# STM32L4x2 register map
File version: 2.3
CPU: CM4 r0p1, little endian, MPU, FPU, 4 interrupt priority bits
Registers are 32-bit, read-write, reset 0x0 unless marked. A register's access mark holds for its fields unless they carry their own. Offsets are from the block's base; [hi:lo] are bit positions; 'fields as' and 'values as' point back to an identical list.

## CRS — Clock recovery system
Base 0x40006000
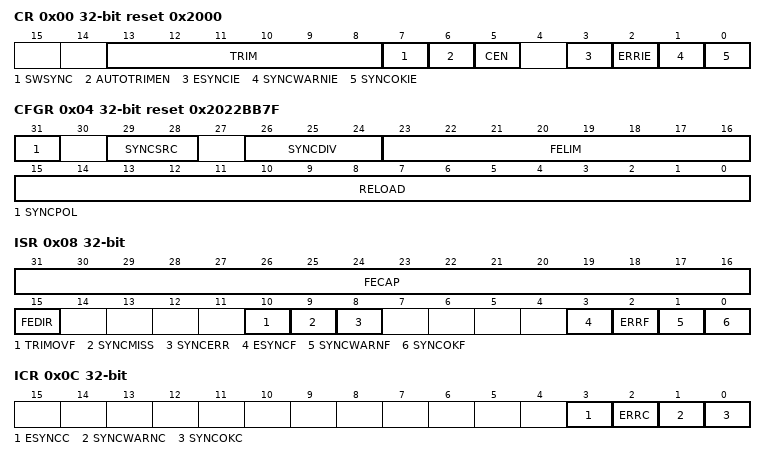
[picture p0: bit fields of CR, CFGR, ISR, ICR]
0x00 CR reset 0x2000 — control register
  [13:8] TRIM — HSI48 oscillator smooth trimming
  [7] SWSYNC — Generate software SYNC event
    1=Sync (A software sync is generated)
  [6] AUTOTRIMEN — Automatic trimming enable
    0=Disabled (Automatic trimming disabled); 1=Enabled (Automatic trimming enabled)
  [5] CEN — Frequency error counter enable
    0=Disabled (Frequency error counter disabled); 1=Enabled (Frequency error counter enabled)
  [3] ESYNCIE — Expected SYNC interrupt enable
    0=Disabled (Interrupt disabled); 1=Enabled (Interrupt enabled)
  [2] ERRIE — Synchronization or trimming error interrupt enable
    values as ESYNCIE
  [1] SYNCWARNIE — SYNC warning interrupt enable
    values as ESYNCIE
  [0] SYNCOKIE — SYNC event OK interrupt enable
    values as ESYNCIE
0x04 CFGR reset 0x2022BB7F — configuration register
  [31] SYNCPOL — SYNC polarity selection
    0=RisingEdge (SYNC active on rising edge); 1=FallingEdge (SYNC active on falling edge)
  [29:28] SYNCSRC — SYNC signal source selection
    0=GPIO_AF (GPIO AF (crs_sync_in_1) selected as SYNC signal source); 1=LSE (LSE (crs_sync_in_2) selected as SYNC signal source); 2=USB_SOF (USB SOF (crs_sync_in_3) selected as SYNC signal source)
  [26:24] SYNCDIV — SYNC divider
    0=Div1 (SYNC not divided); 1=Div2 (SYNC divided by 2); 2=Div4 (SYNC divided by 4); 3=Div8 (SYNC divided by 8); 4=Div16 (SYNC divided by 16); 5=Div32 (SYNC divided by 32); 6=Div64 (SYNC divided by 64); 7=Div128 (SYNC divided by 128)
  [23:16] FELIM — Frequency error limit
  [15:0] RELOAD — Counter reload value
0x08 ISR ro — interrupt and status register
  [31:16] FECAP — Frequency error capture
  [15] FEDIR — Frequency error direction
    0=UpCounting (Error in up-counting direction); 1=DownCounting (Error in down-counting direction)
  [10] TRIMOVF — Trimming overflow or underflow
    0=NotSignaled (Signal not set); 1=Signaled (Signal set)
  [9] SYNCMISS — SYNC missed
    0=NotSignaled (Signal not set); 1=Signaled (Signal set)
  [8] SYNCERR — SYNC error
    0=NotSignaled (Signal not set); 1=Signaled (Signal set)
  [3] ESYNCF — Expected SYNC flag
    0=NotSignaled (Signal not set); 1=Signaled (Signal set)
  [2] ERRF — Error flag
    0=NotSignaled (Signal not set); 1=Signaled (Signal set)
  [1] SYNCWARNF — SYNC warning flag
    0=NotSignaled (Signal not set); 1=Signaled (Signal set)
  [0] SYNCOKF — SYNC event OK flag
    0=NotSignaled (Signal not set); 1=Signaled (Signal set)
0x0C ICR — interrupt flag clear register
  [all] fields
    1=Clear flag
  [3] ESYNCC — Expected SYNC clear flag
  [2] ERRC — Error clear flag
  [1] SYNCWARNC — SYNC warning clear flag
  [0] SYNCOKC — SYNC event OK clear flag

## DBGMCU — MCU debug component
Base 0xE0042000
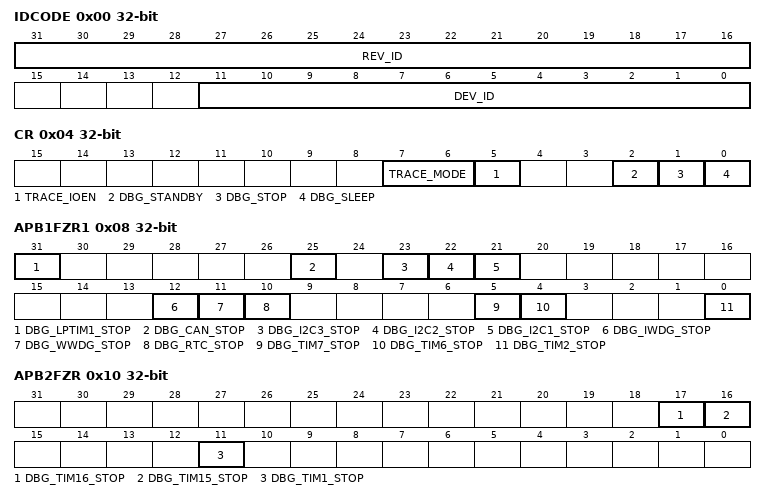
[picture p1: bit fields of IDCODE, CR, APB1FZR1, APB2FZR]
0x00 IDCODE ro — DBGMCU_IDCODE
  [31:16] REV_ID — Revision identifie
  [11:0] DEV_ID — Device identifier
0x04 CR — Debug MCU configuration register
  [7:6] TRACE_MODE — Trace pin assignment control
  [5] TRACE_IOEN — Trace pin assignment control
  [2] DBG_STANDBY — Debug Standby mode
  [1] DBG_STOP — Debug Stop mode
  [0] DBG_SLEEP — Debug Sleep mode
0x08 APB1FZR1 — Debug MCU APB1 freeze register1
  [31] DBG_LPTIM1_STOP — LPTIM1 counter stopped when core is halted
  [25] DBG_CAN_STOP — bxCAN stopped when core is halted
  [23] DBG_I2C3_STOP — I2C3 SMBUS timeout counter stopped when core is halted
  [22] DBG_I2C2_STOP — I2C2 SMBUS timeout counter stopped when core is halted
  [21] DBG_I2C1_STOP — I2C1 SMBUS timeout counter stopped when core is halted
  [12] DBG_IWDG_STOP — Independent watchdog counter stopped when core is halted
  [11] DBG_WWDG_STOP — Window watchdog counter stopped when core is halted
  [10] DBG_RTC_STOP — RTC counter stopped when core is halted
  [5] DBG_TIM7_STOP — TIM7 counter stopped when core is halted
  [4] DBG_TIM6_STOP — TIM6 counter stopped when core is halted
  [0] DBG_TIM2_STOP — TIM2 counter stopped when core is halted
0x0C APB1FZR2 — Debug MCU APB1 freeze register 2
  [5] DBG_LPTIM2_STOP — LPTIM2 counter stopped when core is halted
0x10 APB2FZR — Debug MCU APB2 freeze register
  [17] DBG_TIM16_STOP — TIM16 counter stopped when core is halted
  [16] DBG_TIM15_STOP — TIM15 counter stopped when core is halted
  [11] DBG_TIM1_STOP — TIM1 counter stopped when core is halted
